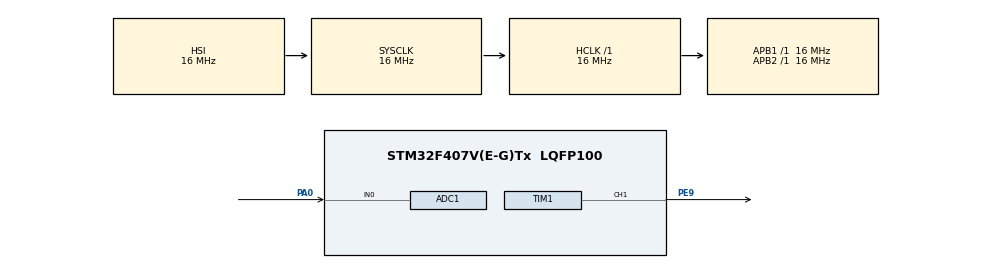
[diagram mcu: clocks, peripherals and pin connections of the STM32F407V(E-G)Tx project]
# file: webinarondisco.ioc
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ADC1.Channel-0\#ChannelRegularConversion=ADC_CHANNEL_0
ADC1.NbrOfConversionFlag=1
ADC1.Rank-0\#ChannelRegularConversion=1
ADC1.SamplingTime-0\#ChannelRegularConversion=ADC_SAMPLETIME_480CYCLES
ADC1.master=1
Mcu.Family=STM32F4
Mcu.Name=STM32F407V(E-G)Tx
Mcu.Package=LQFP100
NVIC.PriorityGroup=NVIC_PRIORITYGROUP_4
NVIC.TIM1_UP_TIM10_IRQn=true\:0\:0\:false\:false\:true\:true\:true\:true
PA0-WKUP.Signal=ADCx_IN0
PA13.Mode=Trace_Asynchronous_SW
PA13.Signal=SYS_JTMS-SWDIO
PA14.Mode=Trace_Asynchronous_SW
PA14.Signal=SYS_JTCK-SWCLK
PB3.Mode=Trace_Asynchronous_SW
PB3.Signal=SYS_JTDO-SWO
PC14-OSC32_IN.Mode=LSE-External-Oscillator
PC14-OSC32_IN.Signal=RCC_OSC32_IN
PC15-OSC32_OUT.Mode=LSE-External-Oscillator
PC15-OSC32_OUT.Signal=RCC_OSC32_OUT
PE9.Signal=S_TIM1_CH1
PH0-OSC_IN.Mode=HSE-External-Oscillator
PH0-OSC_IN.Signal=RCC_OSC_IN
PH1-OSC_OUT.Mode=HSE-External-Oscillator
PH1-OSC_OUT.Signal=RCC_OSC_OUT
ProjectManager.HeapSize=0x200
ProjectManager.StackSize=0x400
ProjectManager.TargetToolchain=STM32CubeIDE
RCC.AHBFreq_Value=16000000
RCC.APB1Freq_Value=16000000
RCC.APB2Freq_Value=16000000
RCC.CortexFreq_Value=16000000
RCC.HSE_VALUE=25000000
RCC.HSI_VALUE=16000000
RCC.SYSCLKFreq_VALUE=16000000
RCC.VCOOutputFreq_Value=192000000
SH.ADCx_IN0.0=ADC1_IN0,IN0
SH.S_TIM1_CH1.0=TIM1_CH1,PWM Generation1 CH1
TIM1.AutoReloadPreload=TIM_AUTORELOAD_PRELOAD_ENABLE
TIM1.Channel-PWM\ Generation1\ CH1=TIM_CHANNEL_1
TIM1.Period=2500-1
TIM1.Prescaler=1600-1
TIM1.Pulse-PWM\ Generation1\ CH1=1250
board=custom

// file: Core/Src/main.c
/* USER CODE BEGIN Header */
/**
  ******************************************************************************
  * @file           : main.c
  * @brief          : Main program body
  ******************************************************************************
  * @attention
  *
  * Copyright (c) 2023 STMicroelectronics.
  * All rights reserved.
  *
  * This software is licensed under terms that can be found in the LICENSE file
  * in the root directory of this software component.
  * If no LICENSE file comes with this software, it is provided AS-IS.
  *
  ******************************************************************************
  */
/* USER CODE END Header */
#include "main.h"

/* USER CODE BEGIN Includes */
#include "stdint.h"
/* USER CODE END Includes */

/* USER CODE BEGIN PD */
#define V_REF 		(float)3.3
#define RES_12B 	4096
/* USER CODE END PD */

ADC_HandleTypeDef hadc1;

TIM_HandleTypeDef htim1;

/* USER CODE BEGIN PV */
volatile float voltage = 0;
volatile uint8_t softCounter = 5;
uint32_t clockFreq;
uint32_t hClockFreq;
uint32_t tim1Pscaler;
uint32_t busClock;
uint32_t tim1Arr;
uint32_t pulse;
double pulsewidthperiod;
uint32_t pulsewithfreq;
uint32_t apb2adcclock;
uint32_t resolution;//in cycles
uint32_t sampling;//in cycles
double conversiontime;
double samplingtime;
double totaladctime;
double    totaladcfreq;
/* USER CODE END PV */

void SystemClock_Config(void);
static void MX_GPIO_Init(void);
static void MX_TIM1_Init(void);
static void MX_ADC1_Init(void);

int main(void)
{
  /* USER CODE BEGIN 1 */
clockFreq=HAL_RCC_GetSysClockFreq();
hClockFreq=HAL_RCC_GetHCLKFreq();
busClock=16000000;
apb2adcclock=16000000/2;//pllclck2/2 in Hz
 resolution=15;//in cycles
conversiontime=(double)resolution/apb2adcclock;//in secs
sampling=480; //in cycles
      resolution=15;//in cycles
      totaladctime=(double)(sampling+resolution)/apb2adcclock;//in sec
      totaladcfreq=1/totaladctime;
  /* USER CODE END 1 */

  /* MCU Configuration--------------------------------------------------------*/

  /* Reset of all peripherals, Initializes the Flash interface and the Systick. */
  HAL_Init();

  /* Configure the system clock */
  SystemClock_Config();

  /* Initialize all configured peripherals */
  MX_GPIO_Init();
  MX_TIM1_Init();
  MX_ADC1_Init();
  /* USER CODE BEGIN 2 */
HAL_TIM_PWM_Start_IT(&htim1, TIM_CHANNEL_1);
HAL_ADC_Start(&hadc1);
  /* USER CODE END 2 */

  /* Infinite loop */
  /* USER CODE BEGIN WHILE */
  while (1)
  {
	  tim1Pscaler=htim1.Instance->PSC;
	  tim1Arr=htim1.Instance->ARR;
	  pulse=htim1.Instance->CCR1;
	  pulsewidthperiod=(double)tim1Arr/busClock;//T=1/fclock *arr
	  pulsewithfreq=busClock/tim1Arr;

	  if (HAL_ADC_PollForConversion(&hadc1, 10) == HAL_OK) {
	  voltage = HAL_ADC_GetValue(&hadc1) / (float)RES_12B * V_REF;
	  HAL_ADC_Start(&hadc1);
}
    /* USER CODE END WHILE */

  }
}

void SystemClock_Config(void)
{
  RCC_OscInitTypeDef RCC_OscInitStruct = {0};
  RCC_ClkInitTypeDef RCC_ClkInitStruct = {0};

  /** Configure the main internal regulator output voltage
  */
  __HAL_RCC_PWR_CLK_ENABLE();
  __HAL_PWR_VOLTAGESCALING_CONFIG(PWR_REGULATOR_VOLTAGE_SCALE1);

  /** Initializes the RCC Oscillators according to the specified parameters
  * in the RCC_OscInitTypeDef structure.
  */
  RCC_OscInitStruct.OscillatorType = RCC_OSCILLATORTYPE_HSI;
  RCC_OscInitStruct.HSIState = RCC_HSI_ON;
  RCC_OscInitStruct.HSICalibrationValue = RCC_HSICALIBRATION_DEFAULT;
  RCC_OscInitStruct.PLL.PLLState = RCC_PLL_NONE;
  if (HAL_RCC_OscConfig(&RCC_OscInitStruct) != HAL_OK)
  {
    Error_Handler();
  }

  /** Initializes the CPU, AHB and APB buses clocks
  */
  RCC_ClkInitStruct.ClockType = RCC_CLOCKTYPE_HCLK|RCC_CLOCKTYPE_SYSCLK
                              |RCC_CLOCKTYPE_PCLK1|RCC_CLOCKTYPE_PCLK2;
  RCC_ClkInitStruct.SYSCLKSource = RCC_SYSCLKSOURCE_HSI;
  RCC_ClkInitStruct.AHBCLKDivider = RCC_SYSCLK_DIV1;
  RCC_ClkInitStruct.APB1CLKDivider = RCC_HCLK_DIV1;
  RCC_ClkInitStruct.APB2CLKDivider = RCC_HCLK_DIV1;

  if (HAL_RCC_ClockConfig(&RCC_ClkInitStruct, FLASH_LATENCY_0) != HAL_OK)
  {
    Error_Handler();
  }
}

static void MX_ADC1_Init(void)
{

  ADC_ChannelConfTypeDef sConfig = {0};

  /** Configure the global features of the ADC (Clock, Resolution, Data Alignment and number of conversion)
  */
  hadc1.Instance = ADC1;
  hadc1.Init.ClockPrescaler = ADC_CLOCK_SYNC_PCLK_DIV2;
  hadc1.Init.Resolution = ADC_RESOLUTION_12B;
  hadc1.Init.ScanConvMode = DISABLE;
  hadc1.Init.ContinuousConvMode = DISABLE;
  hadc1.Init.DiscontinuousConvMode = DISABLE;
  hadc1.Init.ExternalTrigConvEdge = ADC_EXTERNALTRIGCONVEDGE_NONE;
  hadc1.Init.ExternalTrigConv = ADC_SOFTWARE_START;
  hadc1.Init.DataAlign = ADC_DATAALIGN_RIGHT;
  hadc1.Init.NbrOfConversion = 1;
  hadc1.Init.DMAContinuousRequests = DISABLE;
  hadc1.Init.EOCSelection = ADC_EOC_SINGLE_CONV;
  if (HAL_ADC_Init(&hadc1) != HAL_OK)
  {
    Error_Handler();
  }

  /** Configure for the selected ADC regular channel its corresponding rank in the sequencer and its sample time.
  */
  sConfig.Channel = ADC_CHANNEL_0;
  sConfig.Rank = 1;
  sConfig.SamplingTime = ADC_SAMPLETIME_480CYCLES;
  if (HAL_ADC_ConfigChannel(&hadc1, &sConfig) != HAL_OK)
  {
    Error_Handler();
  }

}

static void MX_TIM1_Init(void)
{

  TIM_MasterConfigTypeDef sMasterConfig = {0};
  TIM_OC_InitTypeDef sConfigOC = {0};
  TIM_BreakDeadTimeConfigTypeDef sBreakDeadTimeConfig = {0};

  htim1.Instance = TIM1;
  htim1.Init.Prescaler = 1600-1;
  htim1.Init.CounterMode = TIM_COUNTERMODE_UP;
  htim1.Init.Period = 2500-1;
  htim1.Init.ClockDivision = TIM_CLOCKDIVISION_DIV1;
  htim1.Init.RepetitionCounter = 0;
  htim1.Init.AutoReloadPreload = TIM_AUTORELOAD_PRELOAD_ENABLE;
  if (HAL_TIM_PWM_Init(&htim1) != HAL_OK)
  {
    Error_Handler();
  }
  sMasterConfig.MasterOutputTrigger = TIM_TRGO_RESET;
  sMasterConfig.MasterSlaveMode = TIM_MASTERSLAVEMODE_DISABLE;
  if (HAL_TIMEx_MasterConfigSynchronization(&htim1, &sMasterConfig) != HAL_OK)
  {
    Error_Handler();
  }
  sConfigOC.OCMode = TIM_OCMODE_PWM1;
  sConfigOC.Pulse = 1250;
  sConfigOC.OCPolarity = TIM_OCPOLARITY_HIGH;
  sConfigOC.OCNPolarity = TIM_OCNPOLARITY_HIGH;
  sConfigOC.OCFastMode = TIM_OCFAST_DISABLE;
  sConfigOC.OCIdleState = TIM_OCIDLESTATE_RESET;
  sConfigOC.OCNIdleState = TIM_OCNIDLESTATE_RESET;
  if (HAL_TIM_PWM_ConfigChannel(&htim1, &sConfigOC, TIM_CHANNEL_1) != HAL_OK)
  {
    Error_Handler();
  }
  sBreakDeadTimeConfig.OffStateRunMode = TIM_OSSR_DISABLE;
  sBreakDeadTimeConfig.OffStateIDLEMode = TIM_OSSI_DISABLE;
  sBreakDeadTimeConfig.LockLevel = TIM_LOCKLEVEL_OFF;
  sBreakDeadTimeConfig.DeadTime = 0;
  sBreakDeadTimeConfig.BreakState = TIM_BREAK_DISABLE;
  sBreakDeadTimeConfig.BreakPolarity = TIM_BREAKPOLARITY_HIGH;
  sBreakDeadTimeConfig.AutomaticOutput = TIM_AUTOMATICOUTPUT_DISABLE;
  if (HAL_TIMEx_ConfigBreakDeadTime(&htim1, &sBreakDeadTimeConfig) != HAL_OK)
  {
    Error_Handler();
  }
  HAL_TIM_MspPostInit(&htim1);

}

static void MX_GPIO_Init(void)
{

  /* GPIO Ports Clock Enable */
  __HAL_RCC_GPIOC_CLK_ENABLE();
  __HAL_RCC_GPIOH_CLK_ENABLE();
  __HAL_RCC_GPIOA_CLK_ENABLE();
  __HAL_RCC_GPIOE_CLK_ENABLE();
  __HAL_RCC_GPIOB_CLK_ENABLE();

}

/* USER CODE BEGIN 4 */
void HAL_TIM_PWM_PulseFinishedCallback(TIM_HandleTypeDef *htim)
{
	if (softCounter >= 15)
		softCounter = 1;

	softCounter++;
}
void HAL_TIM_PeriodElapsedCallback(TIM_HandleTypeDef *htim)
{
	if (softCounter >= 15)
		softCounter = 5;

	softCounter++;
}
/* USER CODE END 4 */

void Error_Handler(void)
{
  __disable_irq();
  while (1)
  {
  }
}
